# iostr755 register map
Registers are 16-bit, access not given, no defined reset value unless marked. A register's access mark holds for its fields unless they carry their own. Addresses are absolute; registers are grouped by the start of their names; [hi:lo] are bit positions; {n}, {i} and the like mark numbered series.

## PWM
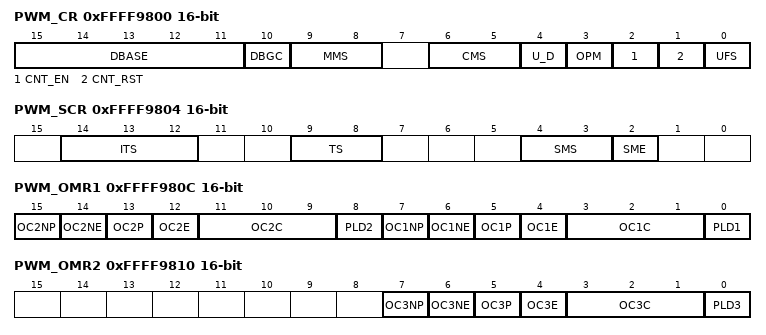
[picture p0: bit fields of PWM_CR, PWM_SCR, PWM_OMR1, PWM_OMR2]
0xFFFF9800 PWM_CR
  [15:11] DBASE, [10] DBGC, [9:8] MMS, [6:5] CMS, [4] U_D, [3] OPM, [2] CNT_EN, [1] CNT_RST, [0] UFS
0xFFFF9804 PWM_SCR
  [14:12] ITS, [9:8] TS, [4:3] SMS, [2] SME
0xFFFF980C PWM_OMR1
  [15] OC2NP, [14] OC2NE, [13] OC2P, [12] OC2E, [11:9] OC2C, [8] PLD2, [7] OC1NP, [6] OC1NE, [5] OC1P, [4] OC1E, [3:1] OC1C, [0] PLD1
0xFFFF9810 PWM_OMR2
  [7] OC3NP, [6] OC3NE, [5] OC3P, [4] OC3E, [3:1] OC3C, [0] PLD3
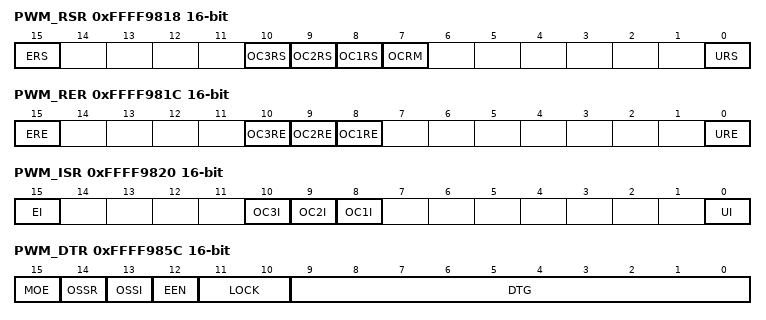
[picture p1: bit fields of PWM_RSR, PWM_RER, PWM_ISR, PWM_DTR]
0xFFFF9818 PWM_RSR
  [15] ERS, [10] OC3RS, [9] OC2RS, [8] OC1RS, [7] OCRM, [0] URS
0xFFFF981C PWM_RER
  [15] ERE, [10] OC3RE, [9] OC2RE, [8] OC1RE, [0] URE
0xFFFF9820 PWM_ISR
  [15] EI, [10] OC3I, [9] OC2I, [8] OC1I, [0] UI
0xFFFF9824 PWM_CNT
0xFFFF9828 PWM_PSC
0xFFFF982C PWM_RCR
  [7:0] REP
0xFFFF9830 PWM_ARR
{0xFFFF9830+4i} PWM_OCR{i} (i=1..3)
0xFFFF985C PWM_DTR
  [15] MOE, [14] OSSR, [13] OSSI, [12] EEN, [11:10] LOCK, [9:0] DTG
0xFFFF9860 PWM_DMAB

## I2C0
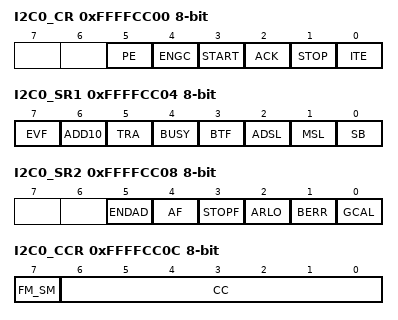
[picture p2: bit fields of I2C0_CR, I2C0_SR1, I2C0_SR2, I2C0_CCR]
0xFFFFCC00 I2C0_CR 8-bit
  [5] PE, [4] ENGC, [3] START, [2] ACK, [1] STOP, [0] ITE
0xFFFFCC04 I2C0_SR1 8-bit
  [7] EVF, [6] ADD10, [5] TRA, [4] BUSY, [3] BTF, [2] ADSL, [1] MSL, [0] SB
0xFFFFCC08 I2C0_SR2 8-bit
  [5] ENDAD, [4] AF, [3] STOPF, [2] ARLO, [1] BERR, [0] GCAL
0xFFFFCC0C I2C0_CCR 8-bit
  [7] FM_SM, [6:0] CC
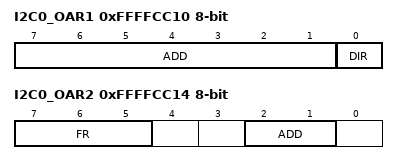
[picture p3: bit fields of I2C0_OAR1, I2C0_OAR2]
0xFFFFCC10 I2C0_OAR1 8-bit
  [7:1] ADD, [0] DIR
0xFFFFCC14 I2C0_OAR2 8-bit
  [7:5] FR, [2:1] ADD
0xFFFFCC18 I2C0_DR 8-bit
0xFFFFCC1C I2C0_ECCR 8-bit
  [4:0] CC

## SSP0
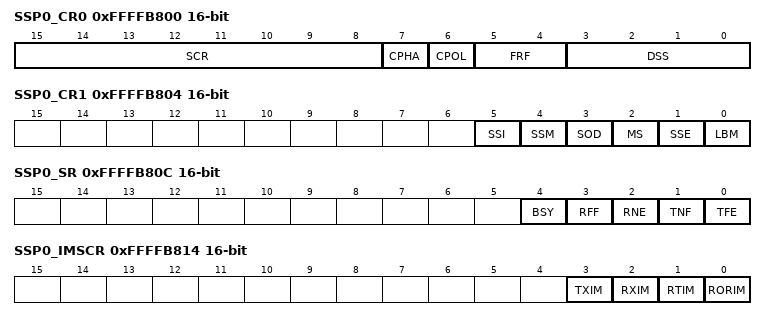
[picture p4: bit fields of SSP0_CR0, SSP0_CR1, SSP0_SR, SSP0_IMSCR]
0xFFFFB800 SSP0_CR0
  [15:8] SCR, [7] CPHA, [6] CPOL, [5:4] FRF, [3:0] DSS
0xFFFFB804 SSP0_CR1
  [5] SSI, [4] SSM, [3] SOD, [2] MS, [1] SSE, [0] LBM
0xFFFFB808 SSP0_DR
0xFFFFB80C SSP0_SR
  [4] BSY, [3] RFF, [2] RNE, [1] TNF, [0] TFE
0xFFFFB810 SSP0_PR
  [7:0] CPSDVSR
0xFFFFB814 SSP0_IMSCR
  [3] TXIM, [2] RXIM, [1] RTIM, [0] RORIM
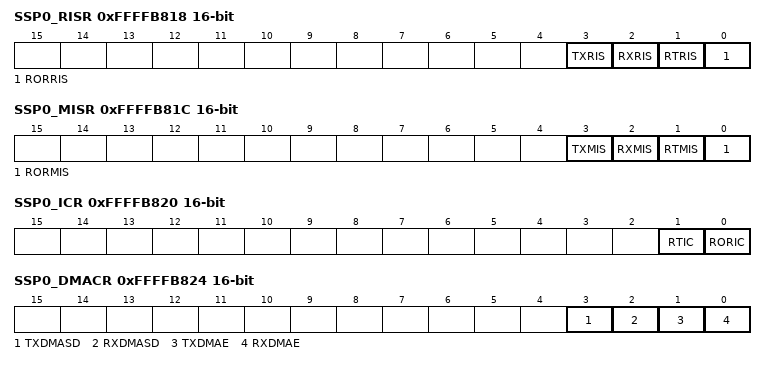
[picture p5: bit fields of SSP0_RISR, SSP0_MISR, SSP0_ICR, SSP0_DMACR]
0xFFFFB818 SSP0_RISR
  [3] TXRIS, [2] RXRIS, [1] RTRIS, [0] RORRIS
0xFFFFB81C SSP0_MISR
  [3] TXMIS, [2] RXMIS, [1] RTMIS, [0] RORMIS
0xFFFFB820 SSP0_ICR
  [1] RTIC, [0] RORIC
0xFFFFB824 SSP0_DMACR
  [3] TXDMASD, [2] RXDMASD, [1] TXDMAE, [0] RXDMAE

## SSP1
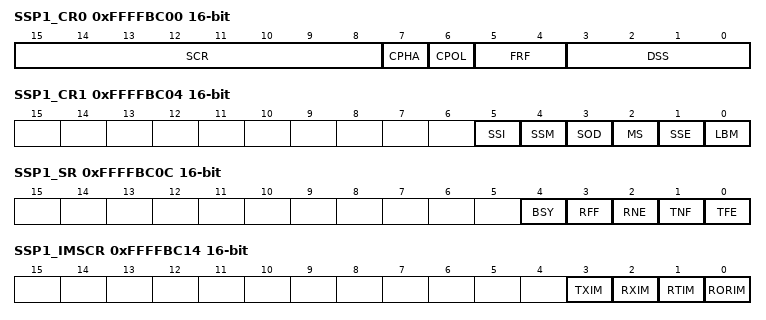
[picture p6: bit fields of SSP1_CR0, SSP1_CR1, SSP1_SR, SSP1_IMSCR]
0xFFFFBC00 SSP1_CR0
  [15:8] SCR, [7] CPHA, [6] CPOL, [5:4] FRF, [3:0] DSS
0xFFFFBC04 SSP1_CR1
  [5] SSI, [4] SSM, [3] SOD, [2] MS, [1] SSE, [0] LBM
0xFFFFBC08 SSP1_DR
0xFFFFBC0C SSP1_SR
  [4] BSY, [3] RFF, [2] RNE, [1] TNF, [0] TFE
0xFFFFBC10 SSP1_PR
  [7:0] CPSDVSR
0xFFFFBC14 SSP1_IMSCR
  [3] TXIM, [2] RXIM, [1] RTIM, [0] RORIM
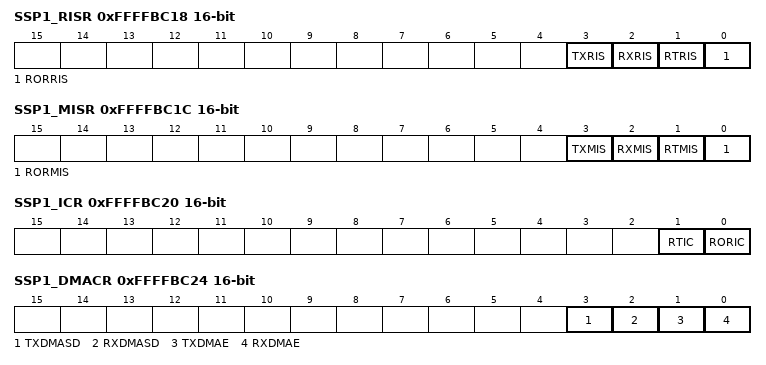
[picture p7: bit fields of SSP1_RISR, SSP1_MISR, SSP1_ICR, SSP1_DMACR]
0xFFFFBC18 SSP1_RISR
  [3] TXRIS, [2] RXRIS, [1] RTRIS, [0] RORRIS
0xFFFFBC1C SSP1_MISR
  [3] TXMIS, [2] RXMIS, [1] RTMIS, [0] RORMIS
0xFFFFBC20 SSP1_ICR
  [1] RTIC, [0] RORIC
0xFFFFBC24 SSP1_DMACR
  [3] TXDMASD, [2] RXDMASD, [1] TXDMAE, [0] RXDMAE

## UART0
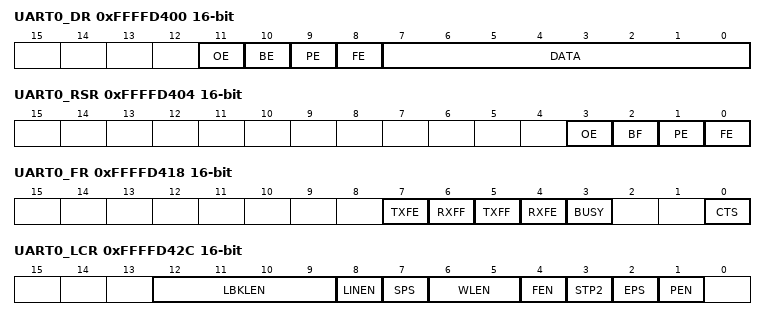
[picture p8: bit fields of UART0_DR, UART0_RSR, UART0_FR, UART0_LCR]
0xFFFFD400 UART0_DR
  [11] OE, [10] BE, [9] PE, [8] FE, [7:0] DATA
0xFFFFD404 UART0_RSR
  [3] OE, [2] BF, [1] PE, [0] FE
0xFFFFD418 UART0_FR
  [7] TXFE, [6] RXFF, [5] TXFF, [4] RXFE, [3] BUSY, [0] CTS
0xFFFFD41C UART0_BKR
  [0] BRK
0xFFFFD424 UART0_IBRD
0xFFFFD428 UART0_FBRD
  [5:0] DIVFRAC
0xFFFFD42C UART0_LCR
  [12:9] LBKLEN, [8] LINEN, [7] SPS, [6:5] WLEN, [4] FEN, [3] STP2, [2] EPS, [1] PEN
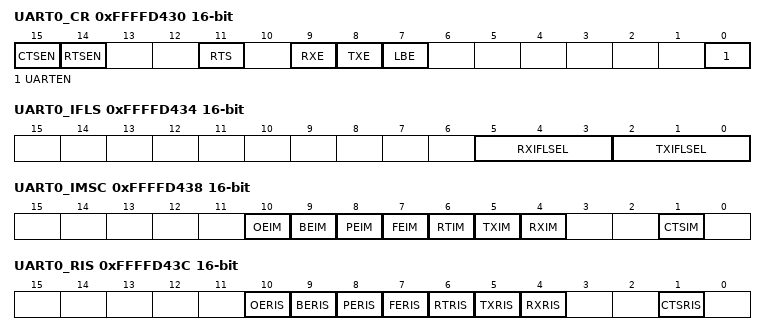
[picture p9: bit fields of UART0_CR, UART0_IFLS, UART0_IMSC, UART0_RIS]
0xFFFFD430 UART0_CR
  [15] CTSEN, [14] RTSEN, [11] RTS, [9] RXE, [8] TXE, [7] LBE, [0] UARTEN
0xFFFFD434 UART0_IFLS
  [5:3] RXIFLSEL, [2:0] TXIFLSEL
0xFFFFD438 UART0_IMSC
  [10] OEIM, [9] BEIM, [8] PEIM, [7] FEIM, [6] RTIM, [5] TXIM, [4] RXIM, [1] CTSIM
0xFFFFD43C UART0_RIS
  [10] OERIS, [9] BERIS, [8] PERIS, [7] FERIS, [6] RTRIS, [5] TXRIS, [4] RXRIS, [1] CTSRIS
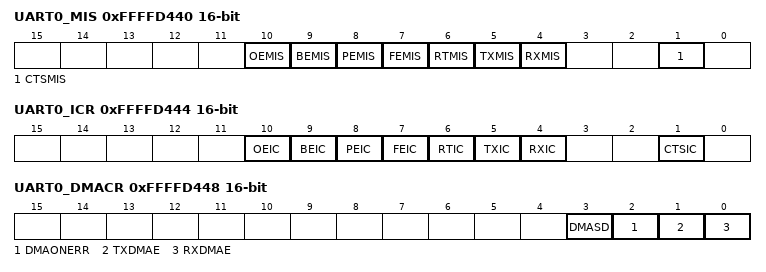
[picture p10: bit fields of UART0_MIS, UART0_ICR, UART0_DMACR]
0xFFFFD440 UART0_MIS
  [10] OEMIS, [9] BEMIS, [8] PEMIS, [7] FEMIS, [6] RTMIS, [5] TXMIS, [4] RXMIS, [1] CTSMIS
0xFFFFD444 UART0_ICR
  [10] OEIC, [9] BEIC, [8] PEIC, [7] FEIC, [6] RTIC, [5] TXIC, [4] RXIC, [1] CTSIC
0xFFFFD448 UART0_DMACR
  [3] DMASD, [2] DMAONERR, [1] TXDMAE, [0] RXDMAE
